# RA4M1 register map
Vendor: Renesas Electronics Corporation; Series: RA4; File version: 1.2
CPU: CM4 r0p1, little endian, MPU, FPU, VTOR, 4 interrupt priority bits
Registers are 8-bit, read-write, reset 0x0 unless marked. A register's access mark holds for its fields unless they carry their own. Offsets are from the block's base; [hi:lo] are bit positions; {n}, {i} and the like mark numbered series; 'fields as' and 'values as' point back to an identical list.

## DTC — Data Transfer Controller
Base 0x40005400
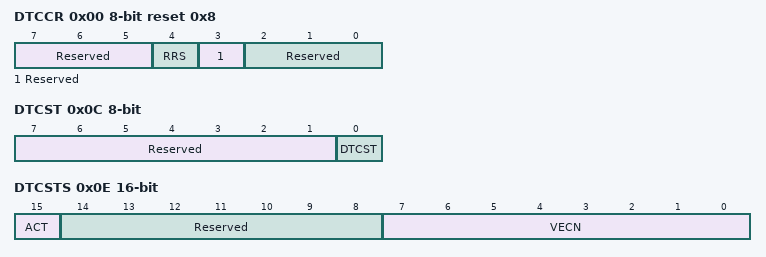
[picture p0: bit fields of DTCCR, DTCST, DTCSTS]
0x00 DTCCR reset 0x8 — DTC Control Register
  [7:5] Reserved — These bits are read as 000. The write value should be 000.
  [4] RRS — DTC Transfer Information Read Skip Enable.
    0=Do not skip transfer information read; 1=Skip transfer information read when vector numbers match
  [3] Reserved — This bit is read as 1. The write value should be 1.
  [2:0] Reserved — These bits are read as 000. The write value should be 000.
0x04 DTCVBR 32-bit — DTC Vector Base Register
  [31:0] DTCVBR — DTC Vector Base Address. Note: A value cannot be set in the lower-order 10 bits. These bits are fixed to 0.
0x0C DTCST — DTC Module Start Register
  [7:1] Reserved — These bits are read as 0000000. The write value should be 0000000.
  [0] DTCST — DTC Module Start
    0=DTC module stop; 1=DTC module start
0x0E DTCSTS 16-bit ro — DTC Status Register
  [15] ACT — DTC Active Flag
    0=DTC transfer operation is not in progress; 1=DTC transfer operation is in progress
  [14:8] Reserved — These bits are read as 0000000.
  [7:0] VECN — DTC-Activating Vector Number Monitoring These bits indicate the vector number for the activating source when DTC transfer is in progress. The value is only valid if DTC transfer is in progress (the value of the ACT flag is 1)

## ELC — Event Link Controller
Base 0x40041000
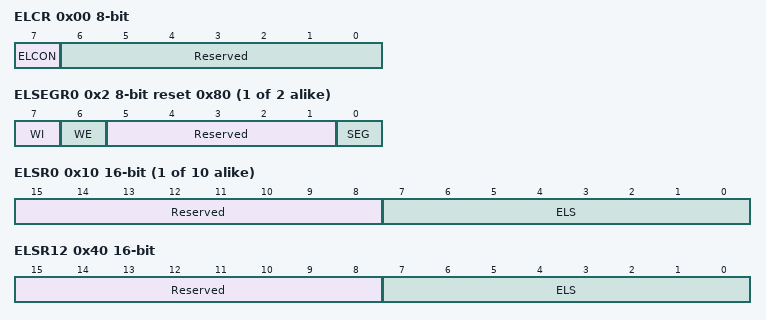
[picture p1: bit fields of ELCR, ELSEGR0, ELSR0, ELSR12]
0x00 ELCR — Event Link Controller Register
  [7] ELCON — All Event Link Enable
    0=ELC function is disabled; 1=ELC function is enabled
  [6:0] Reserved — These bits are read as 0000000. The write value should be 0000000.
{0x2+2i} ELSEGR{i} (i=0..1) reset 0x80 — Event Link Software Event Generation Register {i}
  [7] WI wo — ELSEGR Register Write Disable
    0=Write to ELSEGR register is enabled; 1=Write to ELSEGR register is disabled
  [6] WE — SEG Bit Write Enable
    0=Write to SEG bit is disabled; 1=Write to SEG bit is enabled
  [5:1] Reserved — These bits are read as 00000. The write value should be 00000.
  [0] SEG wo — Software Event Generation
    0=Normal operation; 1=Software event is generated
{0x10+4i} ELSR{i} (i=0..9) 16-bit — Event Link Setting Register {i}
  [15:8] Reserved — These bits are read as 00000000. The write value should be 00000000.
  [7:0] ELS — Event Link Select
    0=Event output to the corresponding peripheral module is disabled; other=others (Set the number for the event signal to be linked.)
0x40 ELSR12 16-bit — Event Link Setting Register 12
  fields as ELSR0
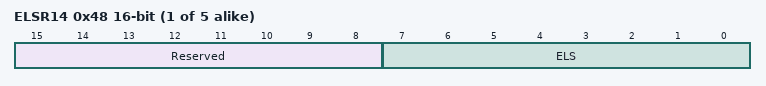
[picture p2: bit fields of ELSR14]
{0x10+4i} ELSR{i} (i=14..18) 16-bit — Event Link Setting Register {i}
  fields as ELSR0

## FCACHE — Flash Cache
Base 0x4001C000
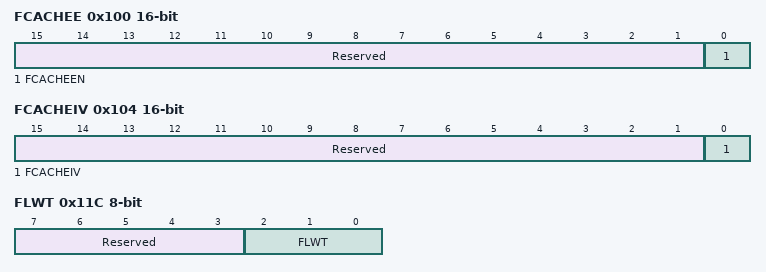
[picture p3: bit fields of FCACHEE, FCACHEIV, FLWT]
0x100 FCACHEE 16-bit — Flash Cache Enable Register
  [15:1] Reserved — These bits are read as 000000000000000. The write value should be 000000000000000.
  [0] FCACHEEN — FCACHE Enable
    0=FCACHE is disabled; 1=FCACHE is enabled
0x104 FCACHEIV 16-bit — Flash Cache Invalidate Register
  [15:1] Reserved — These bits are read as 000000000000000. The write value should be 000000000000000.
  [0] FCACHEIV write-1-sets read-modifies — FCACHE Invalidation
    0=(Read)not in progress / (Write) no effect; 1=(Read)in progress /(Write) Starting Cache Invalidation
0x11C FLWT — Flash Wait Cycle Register
  [7:3] Reserved — These bits are read as 00000. The write value should be 00000.
  [2:0] FLWT — These bits represent the ratio of the CPU clock period to the Flash memory access time.
    0=zero wait; other=others (Setting prohibited)

## PORT0 — Port 0 Control Registers
Base 0x40040000
Same registers: PORT5 0x400400A0, PORT6 0x400400C0, PORT7 0x400400E0, PORT8 0x40040100, PORT9 0x40040120
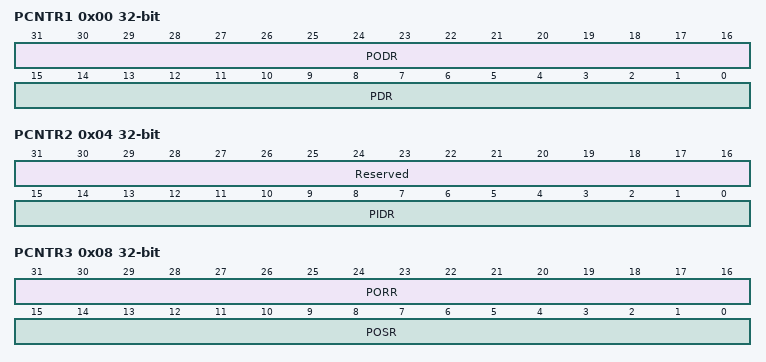
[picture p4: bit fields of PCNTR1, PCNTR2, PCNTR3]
0x00 PCNTR1 32-bit — Port Control Register 1
  [31:16] PODR — Pmn Output Data
    0=Low output; 1=High output
  [15:0] PDR — Pmn Direction
    0=Input (functions as an input pin); 1=Output (functions as an output pin)
0x00 PODR 16-bit (alternate view of PCNTR1) — Output data register
  [15:0] PODR — Pmn Output Data
    0=Low output; 1=High output
0x02 PDR 16-bit (alternate view of PCNTR1) — Data direction register
  [15:0] PDR — Pmn Direction
    values as PCNTR1.PDR
0x04 PCNTR2 32-bit ro (reset mask 0xFFFF0000) — Port Control Register 2
  [31:16] Reserved — These bits are read as 0000000000000000.
  [15:0] PIDR — Pmn Input Data
    0=Low input; 1=High input
0x06 PIDR 16-bit ro reset not defined (alternate view of PCNTR2) — Input data register
  [15:0] PIDR — Pmn Input Data
    0=Low input; 1=High input
0x08 PCNTR3 32-bit wo — Port Control Register 3
  [31:16] PORR — Pmn Output Reset
    0=No affect to output; 1=Low output
  [15:0] POSR — Pmn Output Set
    0=No affect to output; 1=High output
0x08 PORR 16-bit wo (alternate view of PCNTR3) — Output reset register
  [15:0] PORR — Pmn Output Reset
    0=No affect to output; 1=Low output
0x0A POSR 16-bit wo (alternate view of PCNTR3) — Output set register
  [15:0] POSR — Pmn Output Set
    0=No affect to output; 1=High output
